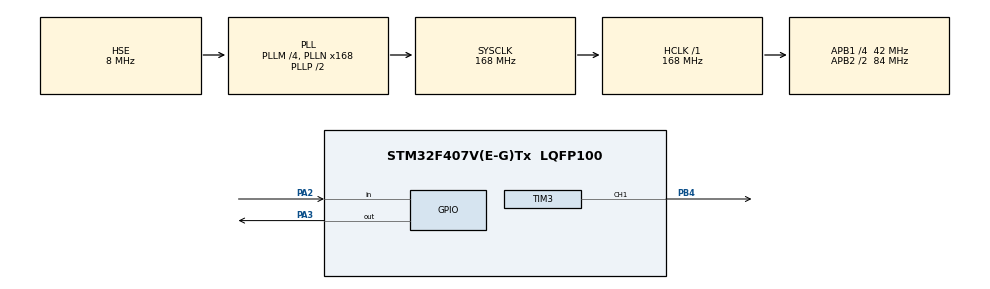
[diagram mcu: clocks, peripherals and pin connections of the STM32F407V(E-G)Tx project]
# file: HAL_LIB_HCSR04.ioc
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Mcu.Family=STM32F4
Mcu.Name=STM32F407V(E-G)Tx
Mcu.Package=LQFP100
NVIC.PriorityGroup=NVIC_PRIORITYGROUP_4
PA2.Signal=GPIO_Input
PA3.Signal=GPIO_Output
PB4.Signal=S_TIM3_CH1
PH0-OSC_IN.Mode=HSE-External-Oscillator
PH0-OSC_IN.Signal=RCC_OSC_IN
PH1-OSC_OUT.Mode=HSE-External-Oscillator
PH1-OSC_OUT.Signal=RCC_OSC_OUT
ProjectManager.HeapSize=0x200
ProjectManager.StackSize=0x400
ProjectManager.TargetToolchain=STM32CubeIDE
RCC.48MHZClocksFreq_Value=84000000
RCC.AHBFreq_Value=168000000
RCC.APB1CLKDivider=RCC_HCLK_DIV4
RCC.APB1Freq_Value=42000000
RCC.APB1TimFreq_Value=84000000
RCC.APB2CLKDivider=RCC_HCLK_DIV2
RCC.APB2Freq_Value=84000000
RCC.APB2TimFreq_Value=168000000
RCC.CortexFreq_Value=168000000
RCC.HCLKFreq_Value=168000000
RCC.HSE_VALUE=8000000
RCC.HSI_VALUE=16000000
RCC.LSE_VALUE=32768
RCC.PLLM=4
RCC.PLLN=168
RCC.PLLSourceVirtual=RCC_PLLSOURCE_HSE
RCC.SYSCLKFreq_VALUE=168000000
RCC.SYSCLKSource=RCC_SYSCLKSOURCE_PLLCLK
RCC.VCOOutputFreq_Value=336000000
SH.S_TIM3_CH1.0=TIM3_CH1,PWM Generation1 CH1
TIM3.Channel-PWM\ Generation1\ CH1=TIM_CHANNEL_1
TIM3.Period=19999
TIM3.Prescaler=83
board=custom

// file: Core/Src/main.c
/* USER CODE BEGIN Header */
/**
  ******************************************************************************
  * @file           : main.c
  * @brief          : Main program body
  ******************************************************************************
  * @attention
  *
  * Copyright (c) 2022 STMicroelectronics.
  * All rights reserved.
  *
  * This software is licensed under terms that can be found in the LICENSE file
  * in the root directory of this software component.
  * If no LICENSE file comes with this software, it is provided AS-IS.
  *
  ******************************************************************************
  */
/* USER CODE END Header */
#include "main.h"

/* USER CODE BEGIN Includes */
#include "dwt_stm32_delay.h"
/* USER CODE END Includes */

TIM_HandleTypeDef htim3;

/* USER CODE BEGIN PV */

uint32_t zaman;
uint16_t mesafe;
uint32_t mapped;
/* USER CODE END PV */

void SystemClock_Config(void);
static void MX_GPIO_Init(void);
static void MX_TIM3_Init(void);

/* USER CODE BEGIN 0 */
uint32_t map(uint32_t sens_giris, uint32_t gir_min, uint32_t gir_max, uint32_t cik_min, uint32_t cik_max){
	return ((((sens_giris - gir_min)*(cik_max - cik_min)) / (gir_max - gir_min)) + cik_min);
}

uint32_t HCSR_Oku(){

	uint32_t time = 0;

	HAL_GPIO_WritePin(GPIOA,GPIO_PIN_3,GPIO_PIN_SET);
	DWT_Delay_us(10);
	HAL_GPIO_WritePin(GPIOA,GPIO_PIN_3,GPIO_PIN_RESET);

	while(!HAL_GPIO_ReadPin(GPIOA,GPIO_PIN_2));

	while(HAL_GPIO_ReadPin(GPIOA,GPIO_PIN_2)){
		time++;
		DWT_Delay_us(1);
	}

	return time;

}

void uzaklik_sur(uint8_t mesafe){

	mapped = map(mesafe, 5, 200, 1500, 2000);
	//__HAL_TIM_SET_COMPARE(&htim3, TIM_CHANNEL_1, 1500);
	//HAL_Delay(1000);
	__HAL_TIM_SET_COMPARE(&htim3, TIM_CHANNEL_1, mapped);
}

/* USER CODE END 0 */

int main(void)
{

  /* MCU Configuration--------------------------------------------------------*/

  /* Reset of all peripherals, Initializes the Flash interface and the Systick. */
  HAL_Init();

  /* Configure the system clock */
  SystemClock_Config();

  /* Initialize all configured peripherals */
  MX_GPIO_Init();
  MX_TIM3_Init();
  /* USER CODE BEGIN 2 */
  DWT_Delay_Init();
  HAL_TIM_PWM_Start(&htim3, TIM_CHANNEL_1);
  /* USER CODE END 2 */

  /* Infinite loop */
  while (1)
  {

    /* USER CODE BEGIN 3 */
	  zaman = HCSR_Oku();

	  mesafe = zaman/58;
	  uzaklik_sur(mesafe);

  }
  /* USER CODE END 3 */
}

void SystemClock_Config(void)
{
  RCC_OscInitTypeDef RCC_OscInitStruct = {0};
  RCC_ClkInitTypeDef RCC_ClkInitStruct = {0};

  /** Configure the main internal regulator output voltage
  */
  __HAL_RCC_PWR_CLK_ENABLE();
  __HAL_PWR_VOLTAGESCALING_CONFIG(PWR_REGULATOR_VOLTAGE_SCALE1);
  /** Initializes the RCC Oscillators according to the specified parameters
  * in the RCC_OscInitTypeDef structure.
  */
  RCC_OscInitStruct.OscillatorType = RCC_OSCILLATORTYPE_HSE;
  RCC_OscInitStruct.HSEState = RCC_HSE_ON;
  RCC_OscInitStruct.PLL.PLLState = RCC_PLL_ON;
  RCC_OscInitStruct.PLL.PLLSource = RCC_PLLSOURCE_HSE;
  RCC_OscInitStruct.PLL.PLLM = 4;
  RCC_OscInitStruct.PLL.PLLN = 168;
  RCC_OscInitStruct.PLL.PLLP = RCC_PLLP_DIV2;
  RCC_OscInitStruct.PLL.PLLQ = 4;
  if (HAL_RCC_OscConfig(&RCC_OscInitStruct) != HAL_OK)
  {
    Error_Handler();
  }
  /** Initializes the CPU, AHB and APB buses clocks
  */
  RCC_ClkInitStruct.ClockType = RCC_CLOCKTYPE_HCLK|RCC_CLOCKTYPE_SYSCLK
                              |RCC_CLOCKTYPE_PCLK1|RCC_CLOCKTYPE_PCLK2;
  RCC_ClkInitStruct.SYSCLKSource = RCC_SYSCLKSOURCE_PLLCLK;
  RCC_ClkInitStruct.AHBCLKDivider = RCC_SYSCLK_DIV1;
  RCC_ClkInitStruct.APB1CLKDivider = RCC_HCLK_DIV4;
  RCC_ClkInitStruct.APB2CLKDivider = RCC_HCLK_DIV2;

  if (HAL_RCC_ClockConfig(&RCC_ClkInitStruct, FLASH_LATENCY_5) != HAL_OK)
  {
    Error_Handler();
  }
}

static void MX_TIM3_Init(void)
{

  TIM_MasterConfigTypeDef sMasterConfig = {0};
  TIM_OC_InitTypeDef sConfigOC = {0};

  htim3.Instance = TIM3;
  htim3.Init.Prescaler = 83;
  htim3.Init.CounterMode = TIM_COUNTERMODE_UP;
  htim3.Init.Period = 19999;
  htim3.Init.ClockDivision = TIM_CLOCKDIVISION_DIV1;
  htim3.Init.AutoReloadPreload = TIM_AUTORELOAD_PRELOAD_DISABLE;
  if (HAL_TIM_PWM_Init(&htim3) != HAL_OK)
  {
    Error_Handler();
  }
  sMasterConfig.MasterOutputTrigger = TIM_TRGO_RESET;
  sMasterConfig.MasterSlaveMode = TIM_MASTERSLAVEMODE_DISABLE;
  if (HAL_TIMEx_MasterConfigSynchronization(&htim3, &sMasterConfig) != HAL_OK)
  {
    Error_Handler();
  }
  sConfigOC.OCMode = TIM_OCMODE_PWM1;
  sConfigOC.Pulse = 0;
  sConfigOC.OCPolarity = TIM_OCPOLARITY_HIGH;
  sConfigOC.OCFastMode = TIM_OCFAST_DISABLE;
  if (HAL_TIM_PWM_ConfigChannel(&htim3, &sConfigOC, TIM_CHANNEL_1) != HAL_OK)
  {
    Error_Handler();
  }
  HAL_TIM_MspPostInit(&htim3);

}

static void MX_GPIO_Init(void)
{
  GPIO_InitTypeDef GPIO_InitStruct = {0};

  /* GPIO Ports Clock Enable */
  __HAL_RCC_GPIOH_CLK_ENABLE();
  __HAL_RCC_GPIOA_CLK_ENABLE();
  __HAL_RCC_GPIOB_CLK_ENABLE();

  /*Configure GPIO pin Output Level */
  HAL_GPIO_WritePin(GPIOA, GPIO_PIN_3, GPIO_PIN_RESET);

  /*Configure GPIO pin : PA2 */
  GPIO_InitStruct.Pin = GPIO_PIN_2;
  GPIO_InitStruct.Mode = GPIO_MODE_INPUT;
  GPIO_InitStruct.Pull = GPIO_NOPULL;
  HAL_GPIO_Init(GPIOA, &GPIO_InitStruct);

  /*Configure GPIO pin : PA3 */
  GPIO_InitStruct.Pin = GPIO_PIN_3;
  GPIO_InitStruct.Mode = GPIO_MODE_OUTPUT_PP;
  GPIO_InitStruct.Pull = GPIO_NOPULL;
  GPIO_InitStruct.Speed = GPIO_SPEED_FREQ_LOW;
  HAL_GPIO_Init(GPIOA, &GPIO_InitStruct);

}

void Error_Handler(void)
{
  __disable_irq();
  while (1)
  {
  }
}
